# ATSAM4LC2A device description
Architecture: CORTEX-M4; Family: SAM4; Series: SAM4L
Registers are 32-bit, read-write, reset 0x0 unless marked. A register's access mark holds for its fields unless they carry their own. Offsets are from the block's base; [hi:lo] are bit positions; {n}, {i} and the like mark numbered series; 'fields as' and 'values as' point back to an identical list; <NAME> marks a mode.

## USART — Universal Synchronous Asynchronous Receiver Transmitter
Instances: USART{n} {0x40024000+0x4000*n} (n=0..3)
0x00 CR wo reset not defined — Control Register
  [21] LINWKUP <LIN_MODE> — Sends a wakeup signal on the LIN bus
  [20] LINABT <LIN_MODE> — Abort the current LIN transmission
  [19] RTSDIS <LIN_MODE> — Request to Send Disable
    0=No effect; 1=Drives the pin RTS to 1
  [18] RTSEN <LIN_MODE> — Request to Send Enable
    0=No effect; 1=Drives the pin RTS to 0
  [17] DTRDIS <LIN_MODE> — Data Terminal Ready Disable
    0=No effect; 1=Drives the pin DTR to 1
  [16] DTREN <LIN_MODE> — Data Terminal Ready Enable
    0=No effect; 1=Drives the pin DTR at 0
  [15] RETTO <LIN_MODE> — Rearm Time-out
    0=No effect; 1=Restart Time-out
  [14] RSTNACK <LIN_MODE> — Reset Non Acknowledge
    0=No effect; 1=Resets NACK in CSR
  [13] RSTIT <LIN_MODE> — Reset Iterations
    0=No effect; 1=Resets ITERATION in CSR. No effect if the ISO7816 is not enabled
  [12] SENDA <LIN_MODE> — Send Address
    0=No effect; 1=In Multi-drop Mode only, the next character written to the THR is sent with the address bit set
  [11] STTTO <LIN_MODE> — Start Time-out
    0=No effect; 1=Starts waiting for a character before clocking the time-out counter
  [10] STPBRK <LIN_MODE> — Stop Break
    0=No effect; 1=Stops transmission of the break after a minimum of one character length and transmits a high level during 12-bit periods.No effect if no break is being transmitted
  [9] STTBRK <LIN_MODE> — Start Break
    0=No effect; 1=Starts transmission of a break after the characters present in THR and the Transmit Shift Register have been transmitted. No effect if a break is already being transmitted
  [8] RSTSTA <LIN_MODE> — Reset Status Bits
    0=No effect; 1=Resets the status bits PARE, FRAME, OVRE and RXBRK in the CSR
  [7] TXDIS <LIN_MODE> — Transmitter Disable
    0=No effect; 1=Disables the transmitter
  [6] TXEN <LIN_MODE> — Transmitter Enable
    0=No effect; 1=Enables the transmitter if TXDIS is 0
  [5] RXDIS <LIN_MODE> — Receiver Disable
    0=No effect; 1=Disables the receiver
  [4] RXEN <LIN_MODE> — Receiver Enable
    0=No effect; 1=Enables the receiver, if RXDIS is 0
  [3] RSTTX <LIN_MODE> — Reset Transmitter
    0=No effect; 1=Resets the transmitter
  [2] RSTRX <LIN_MODE> — Reset Receiver
    0=No effect; 1=Resets the receiver
  [19] RCS <SPI_MASTER_MODE> — Release SPI Chip Select
    0=No effect; 1=Releases the Slave Select Line NSS (RTS pin)
  [18] FCS <SPI_MASTER_MODE> — Force SPI Chip Select
    0=No effect; 1=Forces the Slave Select Line NSS (RTS pin) to 0, even if USART is no transmitting, in order to address SPI slave devices supporting the CSAAT Mode (Chip Select Active After Transfer)
  [17] DTRDIS <SPI_MASTER_MODE> — Data Terminal Ready Disable
    0=No effect; 1=Drives the pin DTR to 1
  [16] DTREN <SPI_MASTER_MODE> — Data Terminal Ready Enable
    0=No effect; 1=Drives the pin DTR at 0
  [15] RETTO <SPI_MASTER_MODE> — Rearm Time-out
    0=No effect; 1=Restart Time-out
  [14] RSTNACK <SPI_MASTER_MODE> — Reset Non Acknowledge
    0=No effect; 1=Resets NACK in CSR
  [13] RSTIT <SPI_MASTER_MODE> — Reset Iterations
    values as RSTIT<LIN_MODE>
  [12] SENDA <SPI_MASTER_MODE> — Send Address
    values as SENDA<LIN_MODE>
  [11] STTTO <SPI_MASTER_MODE> — Start Time-out
    values as STTTO<LIN_MODE>
  [10] STPBRK <SPI_MASTER_MODE> — Stop Break
    values as STPBRK<LIN_MODE>
  [9] STTBRK <SPI_MASTER_MODE> — Start Break
    values as STTBRK<LIN_MODE>
  [8] RSTSTA <SPI_MASTER_MODE> — Reset Status Bits
    values as RSTSTA<LIN_MODE>
  [7] TXDIS <SPI_MASTER_MODE> — Transmitter Disable
    0=No effect; 1=Disables the transmitter
  [6] TXEN <SPI_MASTER_MODE> — Transmitter Enable
    0=No effect; 1=Enables the transmitter if TXDIS is 0
  [5] RXDIS <SPI_MASTER_MODE> — Receiver Disable
    0=No effect; 1=Disables the receiver
  [4] RXEN <SPI_MASTER_MODE> — Receiver Enable
    0=No effect; 1=Enables the receiver, if RXDIS is 0
  [3] RSTTX <SPI_MASTER_MODE> — Reset Transmitter
    0=No effect; 1=Resets the transmitter
  [2] RSTRX <SPI_MASTER_MODE> — Reset Receiver
    0=No effect; 1=Resets the receiver
  [19] RTSDIS <USART_MODE> — Request to Send Disable
    0=No effect; 1=Drives the pin RTS to 1
  [18] RTSEN <USART_MODE> — Request to Send Enable
    0=No effect; 1=Drives the pin RTS to 0
  [17] DTRDIS <USART_MODE> — Data Terminal Ready Disable
    0=No effect; 1=Drives the pin DTR to 1
  [16] DTREN <USART_MODE> — Data Terminal Ready Enable
    0=No effect; 1=Drives the pin DTR at 0
  [15] RETTO <USART_MODE> — Rearm Time-out
    0=No effect; 1=Restart Time-out
  [14] RSTNACK <USART_MODE> — Reset Non Acknowledge
    0=No effect; 1=Resets NACK in CSR
  [13] RSTIT <USART_MODE> — Reset Iterations
    values as RSTIT<LIN_MODE>
  [12] SENDA <USART_MODE> — Send Address
    values as SENDA<LIN_MODE>
  [11] STTTO <USART_MODE> — Start Time-out
    values as STTTO<LIN_MODE>
  [10] STPBRK <USART_MODE> — Stop Break
    values as STPBRK<LIN_MODE>
  [9] STTBRK <USART_MODE> — Start Break
    values as STTBRK<LIN_MODE>
  [8] RSTSTA <USART_MODE> — Reset Status Bits
    values as RSTSTA<LIN_MODE>
  [7] TXDIS <USART_MODE> — Transmitter Disable
    0=No effect; 1=Disables the transmitter
  [6] TXEN <USART_MODE> — Transmitter Enable
    0=No effect; 1=Enables the transmitter if TXDIS is 0
  [5] RXDIS <USART_MODE> — Receiver Disable
    0=No effect; 1=Disables the receiver
  [4] RXEN <USART_MODE> — Receiver Enable
    0=No effect; 1=Enables the receiver, if RXDIS is 0
  [3] RSTTX <USART_MODE> — Reset Transmitter
    0=No effect; 1=Resets the transmitter
  [2] RSTRX <USART_MODE> — Reset Receiver
    0=No effect; 1=Resets the receiver
0x04 MR — Mode Register
  [28] FILTER <SPI_MODE> — Infrared Receive Line Filter
    0=The USART does not filter the receive line; 1=The USART filters the receive line using a three-sample filter (1/16-bit clock) (2 over 3 majority)
  [26:24] MAX_ITERATION <SPI_MODE> — Max interation
  [23] INVDATA <SPI_MODE> — Inverted data
  [21] DSNACK <SPI_MODE> — Disable Successive NACK
    0=NACK is sent on the ISO line as soon as a parity error occurs in the received character (unless INACK is set); 1=Successive parity errors are counted up to the value specified in the MAX_ITERATION field. These parity errors generatea NACK on the ISO line. As soon as this value is reached, no additional NACK is sent on the ISO line. The flag ITERATION is asserted
  [20] INACK <SPI_MODE> — Inhibit Non Acknowledge
    0=The NACK is generated; 1=The NACK is not generated
  [19] OVER <SPI_MODE> — Oversampling Mode
    0=X16 (16x Oversampling); 1=X8 (8x Oversampling)
  [18] CLKO <SPI_MODE> — Clock Output Select
    0=The USART does not drive the SCK pin; 1=The USART drives the SCK pin if USCLKS does not select the external clock SCK
  [17] MODE9 <SPI_MODE> — 9-bit Character Length
    0=CHRL defines character length; 1=9-bit character length
  [16] CPOL <SPI_MODE> — SPI Clock Polarity
    0=ZERO (The inactive state value of SPCK is logic level zero); 1=ONE (The inactive state value of SPCK is logic level one)
  [15:14] CHMODE <SPI_MODE> — Channel Mode
    0=NORMAL (Normal Mode); 1=ECHO (Automatic Echo. Receiver input is connected to the TXD pin); 2=LOCAL_LOOP (Local Loopback. Transmitter output is connected to the Receiver Input); 3=REMOTE_LOOP (Remote Loopback. RXD pin is internally connected to the TXD pin)
  [13:12] NBSTOP <SPI_MODE> — Number of Stop Bits
    0=1 stop bit; 1=1_5 (1.5 stop bits (Only valid if SYNC=0)); 2=2 stop bits
  [11:9] PAR <SPI_MODE> — Parity Type
    0=EVEN (Even parity); 1=ODD (Odd parity); 2=SPACE (Parity forced to 0 (Space)); 3=MARK (Parity forced to 1 (Mark)); 4=NONE (No Parity); 5=No Parity; 6=MULTI (Multi-drop mode); 7=Multi-drop mode
  [8] CPHA <SPI_MODE> — SPI CLock Phase
    0=Data is changed on the leading edge of SPCK and captured on the following edge of SPCK; 1=Data is captured on the leading edge of SPCK and changed on the following edge of SPCK
  [7:6] CHRL <SPI_MODE> — Character Length.
    {v}={v+5} bits (v=0..3)
  [5:4] USCLKS <SPI_MODE> — Clock Selection
    0=MCK; 1=MCK_DIV; 3=SCK
  [3:0] MODE <SPI_MODE> — Usart Mode
    0=NORMAL; 1=RS485; 2=HARDWARE (Hardware Handshaking); 3=MODEM; 4=ISO7816_T0 (IS07816 Protocol: T = 0); 6=ISO7816_T1 (IS07816 Protocol: T = 1); 8=IRDA; 10=LIN_Master; 11=LIN_Slave; 14=SPI_Master; 15=SPI_Slave
  [31] ONEBIT <USART_MODE> — Start Frame Delimiter selector
    0=Start Frame delimiter is COMMAND or DATA SYNC; 1=Start Frame delimiter is One Bit
  [30] MODSYNC <USART_MODE> — Manchester Synchronization Mode
    0=The Manchester Start bit is a 0 to 1 transition; 1=The Manchester Start bit is a 1 to 0 transition
  [29] MAN <USART_MODE> — Manchester Encoder/Decoder Enable
    0=Manchester Encoder/Decoder is disabled; 1=Manchester Encoder/Decoder is enabled
  [28] FILTER <USART_MODE> — Infrared Receive Line Filter
    values as FILTER<SPI_MODE>
  [26:24] MAX_ITERATION <USART_MODE> — Max interation
  [23] INVDATA <USART_MODE> — Inverted data
  [22] VAR_SYNC <USART_MODE> — Variable synchronization of command/data sync Start Frame Delimiter
    0=User defined configuration of command or data sync field depending on SYNC value; 1=The sync field is updated when a character is written into THR register
  [21] DSNACK <USART_MODE> — Disable Successive NACK
    values as DSNACK<SPI_MODE>
  [20] INACK <USART_MODE> — Inhibit Non Acknowledge
    0=The NACK is generated; 1=The NACK is not generated
  [19] OVER <USART_MODE> — Oversampling Mode
    0=X16 (16x Oversampling); 1=X8 (8x Oversampling)
  [18] CLKO <USART_MODE> — Clock Output Select
    values as CLKO<SPI_MODE>
  [17] MODE9 <USART_MODE> — 9-bit Character Length
    0=CHRL defines character length; 1=9-bit character length
  [16] MSBF <USART_MODE> — Bit Order
    0=LSBF (Least Significant Bit first); 1=MSBF (Most Significant Bit first)
  [15:14] CHMODE <USART_MODE> — Channel Mode
    values as CHMODE<SPI_MODE>
  [13:12] NBSTOP <USART_MODE> — Number of Stop Bits
    values as NBSTOP<SPI_MODE>
  [11:9] PAR <USART_MODE> — Parity Type
    values as PAR<SPI_MODE>
  [8] SYNC <USART_MODE> — Synchronous Mode Select
    0=USART operates in Synchronous Mode; 1=USART operates in Asynchronous Mode
  [7:6] CHRL <USART_MODE> — Character Length.
    {v}={v+5} bits (v=0..3)
  [5:4] USCLKS <USART_MODE> — Clock Selection
    0=MCK; 1=MCK_DIV; 3=SCK
  [3:0] MODE <USART_MODE> — Usart Mode
    values as MODE<SPI_MODE>
0x08 IER wo (atomic set of IMR) — Interrupt Enable Register
  [31] LINHTE <LIN_MODE> — LIN Header Timeout Error Interrupt Enable
    0=No Effect; 1=Enables the interrupt
  [30] LINSTE <LIN_MODE> — LIN Synch Tolerance Error Interrupt Enable
    0=No Effect; 1=Enables the interrupt
  [29] LINSNRE <LIN_MODE> — LIN Slave Not Responding Error Interrupt Enable
  [28] LINCE <LIN_MODE> — LIN Checksum Error Interrupt Enable
  [27] LINIPE <LIN_MODE> — LIN Identifier Parity Interrupt Enable
  [26] LINISFE <LIN_MODE> — LIN Inconsistent Synch Field Error Interrupt Enable
  [25] LINBE <LIN_MODE> — LIN Bus Error Interrupt Enable
  [19] CTSIC <LIN_MODE> — Clear to Send Input Change Interrupt Enable
    0=No Effect; 1=Enables the interrupt
  [18] DCDIC <LIN_MODE> — Data Carrier Detect Input Change Interrupt Enable
    0=No Effect; 1=Enables the interrupt
  [17] DSRIC <LIN_MODE> — Data Set Ready Input Change Enable
    0=No Effect; 1=Enables the interrupt
  [16] RIIC <LIN_MODE> — Ring Indicator Input Change Enable
    0=No Effect; 1=Enables the interrupt
  [15] LINTC <LIN_MODE> — LIN Transfer Conpleted Interrupt Enable
  [14] LINID <LIN_MODE> — LIN Identifier Sent or LIN Identifier Received Interrupt Enable
  [13] NACK <LIN_MODE> — Non Acknowledge or LIN Break Sent or LIN Break Received Interrupt Enable
    0=No Effect; 1=Enables the interrupt
  [12] RXBUFF <LIN_MODE> — Buffer Full Interrupt Enable
    0=No Effect; 1=Enables the interrupt
  [11] TXBUFE <LIN_MODE> — Buffer Empty Interrupt Enable
    0=No Effect; 1=Enables the interrupt
  [10] ITER <LIN_MODE> — Iteration Interrupt Enable
    0=No Effect; 1=Enables the interrupt
  [9] TXEMPTY <LIN_MODE> — Transmitter Empty Interrupt Enable
    0=No Effect; 1=Enables the interrupt
  [8] TIMEOUT <LIN_MODE> — Time-out Interrupt Enable
    0=No Effect; 1=Enables the interrupt
  [7] PARE <LIN_MODE> — Parity Error Interrupt Enable
    0=No Effect; 1=Enables the interrupt
  [6] FRAME <LIN_MODE> — Framing Error Interrupt Enable
    0=No Effect; 1=Enables the interrupt
  [5] OVRE <LIN_MODE> — Overrun Error Interrupt Enable
    0=No Effect; 1=Enables the interrupt
  [2] RXBRK <LIN_MODE> — Receiver Break Interrupt Enable
    0=No Effect; 1=Enables the interrupt
  [1] TXRDY <LIN_MODE> — Transmitter Ready Interrupt Enable
    0=No Effect; 1=Enables the interrupt
  [0] RXRDY <LIN_MODE> — Receiver Ready Interrupt Enable
    0=No Effect; 1=Enables the interrupt
  [19] CTSIC <SPI_SLAVE_MODE> — Clear to Send Input Change Interrupt Enable
    0=No Effect; 1=Enables the interrupt
  [18] DCDIC <SPI_SLAVE_MODE> — Data Carrier Detect Input Change Interrupt Enable
    0=No Effect; 1=Enables the interrupt
  [17] DSRIC <SPI_SLAVE_MODE> — Data Set Ready Input Change Enable
    0=No Effect; 1=Enables the interrupt
  [16] RIIC <SPI_SLAVE_MODE> — Ring Indicator Input Change Enable
    0=No Effect; 1=Enables the interrupt
  [13] NACK <SPI_SLAVE_MODE> — Non Acknowledge Interrupt Enable
    0=No Effect; 1=Enables the interrupt
  [12] RXBUFF <SPI_SLAVE_MODE> — Buffer Full Interrupt Enable
    0=No Effect; 1=Enables the interrupt
  [11] TXBUFE <SPI_SLAVE_MODE> — Buffer Empty Interrupt Enable
    0=No Effect; 1=Enables the interrupt
  [10] UNRE <SPI_SLAVE_MODE> — SPI Underrun Error Interrupt Enable
    0=No Effect; 1=Enables the interrupt
  [9] TXEMPTY <SPI_SLAVE_MODE> — Transmitter Empty Interrupt Enable
    0=No Effect; 1=Enables the interrupt
  [8] TIMEOUT <SPI_SLAVE_MODE> — Time-out Interrupt Enable
    0=No Effect; 1=Enables the interrupt
  [7] PARE <SPI_SLAVE_MODE> — Parity Error Interrupt Enable
    0=No Effect; 1=Enables the interrupt
  [6] FRAME <SPI_SLAVE_MODE> — Framing Error Interrupt Enable
    0=No Effect; 1=Enables the interrupt
  [5] OVRE <SPI_SLAVE_MODE> — Overrun Error Interrupt Enable
    0=No Effect; 1=Enables the interrupt
  [2] RXBRK <SPI_SLAVE_MODE> — Receiver Break Interrupt Enable
    0=No Effect; 1=Enables the interrupt
  [1] TXRDY <SPI_SLAVE_MODE> — Transmitter Ready Interrupt Enable
    0=No Effect; 1=Enables the interrupt
  [0] RXRDY <SPI_SLAVE_MODE> — Receiver Ready Interrupt Enable
    0=No Effect; 1=Enables the interrupt
  [24] MANEA <USART_MODE> — Manchester Error Interrupt Enable
    0=No effect; 1=Enables the interrupt
  [20] MANE <USART_MODE> — Manchester Error Interrupt Enable
  [19] CTSIC <USART_MODE> — Clear to Send Input Change Interrupt Enable
    0=No Effect; 1=Enables the interrupt
  [18] DCDIC <USART_MODE> — Data Carrier Detect Input Change Interrupt Enable
    0=No Effect; 1=Enables the interrupt
  [17] DSRIC <USART_MODE> — Data Set Ready Input Change Enable
    0=No Effect; 1=Enables the interrupt
  [16] RIIC <USART_MODE> — Ring Indicator Input Change Enable
    0=No Effect; 1=Enables the interrupt
  [13] NACK <USART_MODE> — Non Acknowledge Interrupt Enable
    0=No Effect; 1=Enables the interrupt
  [12] RXBUFF <USART_MODE> — Buffer Full Interrupt Enable
    0=No Effect; 1=Enables the interrupt
  [11] TXBUFE <USART_MODE> — Buffer Empty Interrupt Enable
    0=No Effect; 1=Enables the interrupt
  [10] ITER <USART_MODE> — Iteration Interrupt Enable
    0=No Effect; 1=Enables the interrupt
  [9] TXEMPTY <USART_MODE> — Transmitter Empty Interrupt Enable
    0=No Effect; 1=Enables the interrupt
  [8] TIMEOUT <USART_MODE> — Time-out Interrupt Enable
    0=No Effect; 1=Enables the interrupt
  [7] PARE <USART_MODE> — Parity Error Interrupt Enable
    0=No Effect; 1=Enables the interrupt
  [6] FRAME <USART_MODE> — Framing Error Interrupt Enable
    0=No Effect; 1=Enables the interrupt
  [5] OVRE <USART_MODE> — Overrun Error Interrupt Enable
    0=No Effect; 1=Enables the interrupt
  [2] RXBRK <USART_MODE> — Receiver Break Interrupt Enable
    0=No Effect; 1=Enables the interrupt
  [1] TXRDY <USART_MODE> — Transmitter Ready Interrupt Enable
    0=No Effect; 1=Enables the interrupt
  [0] RXRDY <USART_MODE> — Receiver Ready Interrupt Enable
    0=No Effect; 1=Enables the interrupt
0x0C IDR wo (atomic clear of IMR) — Interrupt Disable Register
  [31] LINHTE <LIN_MODE> — LIN Header Timeout Error Interrupt Disable
    0=No Effect; 1=Disables the interrupt
  [30] LINSTE <LIN_MODE> — LIN Synch Tolerance Error Interrupt Disable
    0=No Effect; 1=Disables the interrupt
  [29] LINSNRE <LIN_MODE> — LIN Slave Not Responding Error Interrupt Disable
  [28] LINCE <LIN_MODE> — LIN Checksum Error Interrupt Disable
  [27] LINIPE <LIN_MODE> — LIN Identifier Parity Interrupt Disable
  [26] LINISFE <LIN_MODE> — LIN Inconsistent Synch Field Error Interrupt Disable
  [25] LINBE <LIN_MODE> — LIN Bus Error Interrupt Disable
  [19] CTSIC <LIN_MODE> — Clear to Send Input Change Interrupt Disable
    0=No Effect; 1=Disables the interrupt
  [18] DCDIC <LIN_MODE> — Data Carrier Detect Input Change Interrupt Disable
    0=No Effect; 1=Disables the interrupt
  [17] DSRIC <LIN_MODE> — Data Set Ready Input Change Disable
    0=No Effect; 1=Disables the interrupt
  [16] RIIC <LIN_MODE> — Ring Indicator Input Change Disable
    0=No Effect; 1=Disables the interrupt
  [15] LINTC <LIN_MODE> — LIN Transfer Conpleted Interrupt Disable
  [14] LINID <LIN_MODE> — LIN Identifier Sent or LIN Identifier Received Interrupt Disable
  [13] NACK <LIN_MODE> — Non Acknowledge or LIN Break Sent or LIN Break Received Interrupt Disable
    0=No Effect; 1=Disables the interrupt
  [12] RXBUFF <LIN_MODE> — Buffer Full Interrupt Disable
    0=No Effect; 1=Disables the interrupt
  [11] TXBUFE <LIN_MODE> — Buffer Empty Interrupt Disable
    0=No Effect; 1=Disables the interrupt
  [10] ITER <LIN_MODE> — Iteration Interrupt Disable
    0=No Effect; 1=Disables the interrupt
  [9] TXEMPTY <LIN_MODE> — Transmitter Empty Interrupt Disable
    0=No Effect; 1=Disables the interrupt
  [8] TIMEOUT <LIN_MODE> — Time-out Interrupt Disable
    0=No Effect; 1=Disables the interrupt
  [7] PARE <LIN_MODE> — Parity Error Interrupt Disable
    0=No Effect; 1=Disables the interrupt
  [6] FRAME <LIN_MODE> — Framing Error Interrupt Disable
    0=No Effect; 1=Disables the interrupt
  [5] OVRE <LIN_MODE> — Overrun Error Interrupt Disable
    0=No Effect; 1=Disables the interrupt
  [2] RXBRK <LIN_MODE> — Receiver Break Interrupt Disable
    0=No Effect; 1=Disables the interrupt
  [1] TXRDY <LIN_MODE> — Transmitter Ready Interrupt Disable
    0=No Effect; 1=Disables the interrupt
  [0] RXRDY <LIN_MODE> — Receiver Ready Interrupt Disable
    0=No Effect; 1=Disables the interrupt
  [19] CTSIC <SPI_SLAVE_MODE> — Clear to Send Input Change Interrupt Disable
    0=No Effect; 1=Disables the interrupt
  [18] DCDIC <SPI_SLAVE_MODE> — Data Carrier Detect Input Change Interrupt Disable
    0=No Effect; 1=Disables the interrupt
  [17] DSRIC <SPI_SLAVE_MODE> — Data Set Ready Input Change Disable
    0=No Effect; 1=Disables the interrupt
  [16] RIIC <SPI_SLAVE_MODE> — Ring Indicator Input Change Disable
    0=No Effect; 1=Disables the interrupt
  [13] NACK <SPI_SLAVE_MODE> — Non Acknowledge Interrupt Disable
    0=No Effect; 1=Disables the interrupt
  [12] RXBUFF <SPI_SLAVE_MODE> — Buffer Full Interrupt Disable
    0=No Effect; 1=Disables the interrupt
  [11] TXBUFE <SPI_SLAVE_MODE> — Buffer Empty Interrupt Disable
    0=No Effect; 1=Disables the interrupt
  [10] UNRE <SPI_SLAVE_MODE> — SPI Underrun Error Interrupt Disable
    0=No Effect; 1=Disables the interrupt
  [9] TXEMPTY <SPI_SLAVE_MODE> — Transmitter Empty Interrupt Disable
    0=No Effect; 1=Disables the interrupt
  [8] TIMEOUT <SPI_SLAVE_MODE> — Time-out Interrupt Disable
    0=No Effect; 1=Disables the interrupt
  [7] PARE <SPI_SLAVE_MODE> — Parity Error Interrupt Disable
    0=No Effect; 1=Disables the interrupt
  [6] FRAME <SPI_SLAVE_MODE> — Framing Error Interrupt Disable
    0=No Effect; 1=Disables the interrupt
  [5] OVRE <SPI_SLAVE_MODE> — Overrun Error Interrupt Disable
    0=No Effect; 1=Disables the interrupt
  [2] RXBRK <SPI_SLAVE_MODE> — Receiver Break Interrupt Disable
    0=No Effect; 1=Disables the interrupt
  [1] TXRDY <SPI_SLAVE_MODE> — Transmitter Ready Interrupt Disable
    0=No Effect; 1=Disables the interrupt
  [0] RXRDY <SPI_SLAVE_MODE> — Receiver Ready Interrupt Disable
    0=No Effect; 1=Disables the interrupt
  [24] MANEA <USART_MODE> — Manchester Error Interrupt Disable
    0=No effect; 1=Disables the corresponding interrupt
  [20] MANE <USART_MODE> — Manchester Error Interrupt Disable
  [19] CTSIC <USART_MODE> — Clear to Send Input Change Interrupt Disable
    0=No Effect; 1=Disables the interrupt
  [18] DCDIC <USART_MODE> — Data Carrier Detect Input Change Interrupt Disable
    0=No Effect; 1=Disables the interrupt
  [17] DSRIC <USART_MODE> — Data Set Ready Input Change Disable
    0=No Effect; 1=Disables the interrupt
  [16] RIIC <USART_MODE> — Ring Indicator Input Change Disable
    0=No Effect; 1=Disables the interrupt
  [13] NACK <USART_MODE> — Non Acknowledge Interrupt Disable
    0=No Effect; 1=Disables the interrupt
  [12] RXBUFF <USART_MODE> — Buffer Full Interrupt Disable
    0=No Effect; 1=Disables the interrupt
  [11] TXBUFE <USART_MODE> — Buffer Empty Interrupt Disable
    0=No Effect; 1=Disables the interrupt
  [10] ITER <USART_MODE> — Iteration Interrupt Disable
    0=No Effect; 1=Disables the interrupt
  [9] TXEMPTY <USART_MODE> — Transmitter Empty Interrupt Disable
    0=No Effect; 1=Disables the interrupt
  [8] TIMEOUT <USART_MODE> — Time-out Interrupt Disable
    0=No Effect; 1=Disables the interrupt
  [7] PARE <USART_MODE> — Parity Error Interrupt Disable
    0=No Effect; 1=Disables the interrupt
  [6] FRAME <USART_MODE> — Framing Error Interrupt Disable
    0=No Effect; 1=Disables the interrupt
  [5] OVRE <USART_MODE> — Overrun Error Interrupt Disable
    0=No Effect; 1=Disables the interrupt
  [2] RXBRK <USART_MODE> — Receiver Break Interrupt Disable
    0=No Effect; 1=Disables the interrupt
  [1] TXRDY <USART_MODE> — Transmitter Ready Interrupt Disable
    0=No Effect; 1=Disables the interrupt
  [0] RXRDY <USART_MODE> — Receiver Ready Interrupt Disable
    0=No Effect; 1=Disables the interrupt
0x10 IMR ro — Interrupt Mask Register
  [31] LINHTE <LIN_MODE> — LIN Header Timeout Error Interrupt Mask
    0=The interrupt is disabled; 1=The interrupt is enabled
  [30] LINSTE <LIN_MODE> — LIN Synch Tolerance Error Interrupt Mask
    0=The interrupt is disabled; 1=The interrupt is enabled
  [29] LINSNRE <LIN_MODE> — LIN Slave Not Responding Error Interrupt Mask
  [28] LINCE <LIN_MODE> — LIN Checksum Error Interrupt Mask
  [27] LINIPE <LIN_MODE> — LIN Identifier Parity Interrupt Mask
  [26] LINISFE <LIN_MODE> — LIN Inconsistent Synch Field Error Interrupt Mask
  [25] LINBE <LIN_MODE> — LIN Bus Error Interrupt Mask
  [19] CTSIC <LIN_MODE> — Clear to Send Input Change Interrupt Mask
    0=The interrupt is disabled; 1=The interrupt is enabled
  [18] DCDIC <LIN_MODE> — Data Carrier Detect Input Change Interrupt Mask
    0=The interrupt is disabled; 1=The interrupt is enabled
  [17] DSRIC <LIN_MODE> — Data Set Ready Input Change Mask
    0=The interrupt is disabled; 1=The interrupt is enabled
  [16] RIIC <LIN_MODE> — Ring Indicator Input Change Mask
    0=The interrupt is disabled; 1=The interrupt is enabled
  [15] LINTC <LIN_MODE> — LIN Transfer Conpleted Interrupt Mask
  [14] LINID <LIN_MODE> — LIN Identifier Sent or LIN Received Interrupt Mask
  [13] NACK <LIN_MODE> — Non Acknowledge or LIN Break Sent or LIN Break Received Interrupt Mask
    0=The interrupt is disabled; 1=The interrupt is enabled
  [12] RXBUFF <LIN_MODE> — Buffer Full Interrupt Mask
    0=The interrupt is disabled; 1=The interrupt is enabled
  [11] TXBUFE <LIN_MODE> — Buffer Empty Interrupt Mask
    0=The interrupt is disabled; 1=The interrupt is enabled
  [10] ITER <LIN_MODE> — Iteration Interrupt Mask
    0=The interrupt is disabled; 1=The interrupt is enabled
  [9] TXEMPTY <LIN_MODE> — TXEMPTY Interrupt Mask
    0=The interrupt is disabled; 1=The interrupt is enabled
  [8] TIMEOUT <LIN_MODE> — Time-out Interrupt Mask
    0=The interrupt is disabled; 1=The interrupt is enabled
  [7] PARE <LIN_MODE> — Parity Error Interrupt Mask
    0=The interrupt is disabled; 1=The interrupt is enabled
  [6] FRAME <LIN_MODE> — Framing Error Interrupt Mask
    0=The interrupt is disabled; 1=The interrupt is enabled
  [5] OVRE <LIN_MODE> — Overrun Error Interrupt Mask
    0=The interrupt is disabled; 1=The interrupt is enabled
  [2] RXBRK <LIN_MODE> — Receiver Break Interrupt Mask
    0=The interrupt is disabled; 1=The interrupt is enabled
  [1] TXRDY <LIN_MODE> — TXRDY Interrupt Mask
    0=The interrupt is disabled; 1=The interrupt is enabled
  [0] RXRDY <LIN_MODE> — RXRDY Interrupt Mask
    0=The interrupt is disabled; 1=The interrupt is enabled
  [19] CTSIC <SPI_SLAVE_MODE> — Clear to Send Input Change Interrupt Mask
    0=The interrupt is disabled; 1=The interrupt is enabled
  [18] DCDIC <SPI_SLAVE_MODE> — Data Carrier Detect Input Change Interrupt Mask
    0=The interrupt is disabled; 1=The interrupt is enabled
  [17] DSRIC <SPI_SLAVE_MODE> — Data Set Ready Input Change Mask
    0=The interrupt is disabled; 1=The interrupt is enabled
  [16] RIIC <SPI_SLAVE_MODE> — Ring Indicator Input Change Mask
    0=The interrupt is disabled; 1=The interrupt is enabled
  [13] NACK <SPI_SLAVE_MODE> — Non Acknowledge Interrupt Mask
    0=The interrupt is disabled; 1=The interrupt is enabled
  [12] RXBUFF <SPI_SLAVE_MODE> — Buffer Full Interrupt Mask
    0=The interrupt is disabled; 1=The interrupt is enabled
  [11] TXBUFE <SPI_SLAVE_MODE> — Buffer Empty Interrupt Mask
    0=The interrupt is disabled; 1=The interrupt is enabled
  [10] UNRE <SPI_SLAVE_MODE> — SPI Underrun Error Interrupt Mask
    0=The interrupt is disabled; 1=The interrupt is enabled
  [9] TXEMPTY <SPI_SLAVE_MODE> — TXEMPTY Interrupt Mask
    0=The interrupt is disabled; 1=The interrupt is enabled
  [8] TIMEOUT <SPI_SLAVE_MODE> — Time-out Interrupt Mask
    0=The interrupt is disabled; 1=The interrupt is enabled
  [7] PARE <SPI_SLAVE_MODE> — Parity Error Interrupt Mask
    0=The interrupt is disabled; 1=The interrupt is enabled
  [6] FRAME <SPI_SLAVE_MODE> — Framing Error Interrupt Mask
    0=The interrupt is disabled; 1=The interrupt is enabled
  [5] OVRE <SPI_SLAVE_MODE> — Overrun Error Interrupt Mask
    0=The interrupt is disabled; 1=The interrupt is enabled
  [2] RXBRK <SPI_SLAVE_MODE> — Receiver Break Interrupt Mask
    0=The interrupt is disabled; 1=The interrupt is enabled
  [1] TXRDY <SPI_SLAVE_MODE> — TXRDY Interrupt Mask
    0=The interrupt is disabled; 1=The interrupt is enabled
  [0] RXRDY <SPI_SLAVE_MODE> — RXRDY Interrupt Mask
    0=The interrupt is disabled; 1=The interrupt is enabled
  [24] MANEA <USART_MODE> — Manchester Error Interrupt Mask
    0=The interrupt is disabled; 1=The interrupt is enabled
  [20] MANE <USART_MODE> — Manchester Error Interrupt Mask
  [19] CTSIC <USART_MODE> — Clear to Send Input Change Interrupt Mask
    0=The interrupt is disabled; 1=The interrupt is enabled
  [18] DCDIC <USART_MODE> — Data Carrier Detect Input Change Interrupt Mask
    0=The interrupt is disabled; 1=The interrupt is enabled
  [17] DSRIC <USART_MODE> — Data Set Ready Input Change Mask
    0=The interrupt is disabled; 1=The interrupt is enabled
  [16] RIIC <USART_MODE> — Ring Indicator Input Change Mask
    0=The interrupt is disabled; 1=The interrupt is enabled
  [13] NACK <USART_MODE> — Non Acknowledge Interrupt Mask
    0=The interrupt is disabled; 1=The interrupt is enabled
  [12] RXBUFF <USART_MODE> — Buffer Full Interrupt Mask
    0=The interrupt is disabled; 1=The interrupt is enabled
  [11] TXBUFE <USART_MODE> — Buffer Empty Interrupt Mask
    0=The interrupt is disabled; 1=The interrupt is enabled
  [10] ITER <USART_MODE> — Iteration Interrupt Mask
    0=The interrupt is disabled; 1=The interrupt is enabled
  [9] TXEMPTY <USART_MODE> — TXEMPTY Interrupt Mask
    0=The interrupt is disabled; 1=The interrupt is enabled
  [8] TIMEOUT <USART_MODE> — Time-out Interrupt Mask
    0=The interrupt is disabled; 1=The interrupt is enabled
  [7] PARE <USART_MODE> — Parity Error Interrupt Mask
    0=The interrupt is disabled; 1=The interrupt is enabled
  [6] FRAME <USART_MODE> — Framing Error Interrupt Mask
    0=The interrupt is disabled; 1=The interrupt is enabled
  [5] OVRE <USART_MODE> — Overrun Error Interrupt Mask
    0=The interrupt is disabled; 1=The interrupt is enabled
  [2] RXBRK <USART_MODE> — Receiver Break Interrupt Mask
    0=The interrupt is disabled; 1=The interrupt is enabled
  [1] TXRDY <USART_MODE> — TXRDY Interrupt Mask
    0=The interrupt is disabled; 1=The interrupt is enabled
  [0] RXRDY <USART_MODE> — RXRDY Interrupt Mask
    0=The interrupt is disabled; 1=The interrupt is enabled
0x14 CSR ro — Channel Status Register
  [31] LINHTE <LIN_MODE> — LIN Header Timeout Error
    0=COMM_RX is at 0; 1=COMM_RX is at 1
  [30] LINSTE <LIN_MODE> — LIN Synch Tolerance Error
    0=COMM_TX is at 0; 1=COMM_TX is at 1
  [29] LINSNRE <LIN_MODE> — LIN Slave Not Responding Error
  [28] LINCE <LIN_MODE> — LIN Checksum Error
  [27] LINIPE <LIN_MODE> — LIN Identifier Parity Error
  [26] LINISFE <LIN_MODE> — LIN Inconsistent Synch Field Error
  [25] LINBE <LIN_MODE> — LIN Bit Error
  [23] LINBLS <LIN_MODE> — LIN Bus Line Status
    0=CTS is at 0; 1=CTS is at 1
  [22] DCD <LIN_MODE> — Image of DCD Input
    0=DCD is at 0; 1=DCD is at 1
  [21] DSR <LIN_MODE> — Image of DSR Input
    0=DSR is at 0; 1=DSR is at 1
  [20] RI <LIN_MODE> — Image of RI Input
    0=RI is at 0; 1=RI is at 1
  [19] CTSIC <LIN_MODE> — Clear to Send Input Change Flag
    0=No input change has been detected on the CTS pin since the last read of CSR; 1=At least one input change has been detected on the CTS pin since the last read of CSR
  [18] DCDIC <LIN_MODE> — Data Carrier Detect Input Change Flag
    0=No input change has been detected on the DCD pin since the last read of CSR; 1=At least one input change has been detected on the DCD pin since the last read of CSR
  [17] DSRIC <LIN_MODE> — Data Set Ready Input Change Flag
    0=No input change has been detected on the DSR pin since the last read of CSR; 1=At least one input change has been detected on the DSR pin since the last read of CSR
  [16] RIIC <LIN_MODE> — Ring Indicator Input Change Flag
    0=No input change has been detected on the RI pin since the last read of CSR; 1=At least one input change has been detected on the RI pin since the last read of CSR
  [15] LINTC <LIN_MODE> — LIN Transfer Conpleted
  [14] LINID <LIN_MODE> — LIN Identifier Sent or LIN Identifier Received
  [13] NACK <LIN_MODE> — Non Acknowledge or LIN Break Sent or LIN Break Received
    0=No Non Acknowledge has not been detected since the last RSTNACK; 1=At least one Non Acknowledge has been detected since the last RSTNACK
  [12] RXBUFF <LIN_MODE> — Reception Buffer Full
    0=The signal Buffer Full from the Receive PDC channel is inactive; 1=The signal Buffer Full from the Receive PDC channel is active
  [11] TXBUFE <LIN_MODE> — Transmission Buffer Empty
    0=The signal Buffer Empty from the Transmit PDC channel is inactive; 1=The signal Buffer Empty from the Transmit PDC channel is active
  [10] ITER <LIN_MODE> — Max number of Repetitions Reached
    0=Maximum number of repetitions has not been reached since the last RSIT; 1=Maximum number of repetitions has been reached since the last RSIT
  [9] TXEMPTY <LIN_MODE> — Transmitter Empty
    0=There are characters in either THR or the Transmit Shift Register, or the transmitter is disabled; 1=There is at least one character in either THR or the Transmit Shift Register
  [8] TIMEOUT <LIN_MODE> — Receiver Time-out
    0=There has not been a time-out since the last Start Time-out command or the Time-out Register is 0; 1=There has been a time-out since the last Start Time-out command
  [7] PARE <LIN_MODE> — Parity Error
    0=No parity error has been detected since the last RSTSTA; 1=At least one parity error has been detected since the last RSTSTA
  [6] FRAME <LIN_MODE> — Framing Error
    0=No stop bit has been detected low since the last RSTSTA; 1=At least one stop bit has been detected low since the last RSTSTA
  [5] OVRE <LIN_MODE> — Overrun Error
    0=No overrun error has occurred since since the last RSTSTA; 1=At least one overrun error has occurred since the last RSTSTA
  [2] RXBRK <LIN_MODE> — Break Received/End of Break
    0=No Break received or End of Break detected since the last RSTSTA; 1=Break Received or End of Break detected since the last RSTSTA
  [1] TXRDY <LIN_MODE> — Transmitter Ready
    0=A character is in the THR waiting to be transferred to the Transmit Shift Register, or an STTBRK command has been requested, or the transmitter is disabled. As soon as the transmitter is enabled, TXRDY becomes 1; 1=There is no character in the THR
  [0] RXRDY <LIN_MODE> — Receiver Ready
    0=No complete character has been received since the last read of RHR or the receiver is disabled. If characters werebeing received when the receiver was disabled, RXRDY changes to 1 when the receiver is enabled; 1=At least one complete character has been received and RHR has not yet been read
  [23] CTS <SPI_SLAVE_MODE> — Image of CTS Input
    0=CTS is at 0; 1=CTS is at 1
  [22] DCD <SPI_SLAVE_MODE> — Image of DCD Input
    0=DCD is at 0; 1=DCD is at 1
  [21] DSR <SPI_SLAVE_MODE> — Image of DSR Input
    0=DSR is at 0; 1=DSR is at 1
  [20] RI <SPI_SLAVE_MODE> — Image of RI Input
    0=RI is at 0; 1=RI is at 1
  [19] CTSIC <SPI_SLAVE_MODE> — Clear to Send Input Change Flag
    values as CTSIC<LIN_MODE>
  [18] DCDIC <SPI_SLAVE_MODE> — Data Carrier Detect Input Change Flag
    values as DCDIC<LIN_MODE>
  [17] DSRIC <SPI_SLAVE_MODE> — Data Set Ready Input Change Flag
    values as DSRIC<LIN_MODE>
  [16] RIIC <SPI_SLAVE_MODE> — Ring Indicator Input Change Flag
    values as RIIC<LIN_MODE>
  [13] NACK <SPI_SLAVE_MODE> — Non Acknowledge
    values as NACK<LIN_MODE>
  [12] RXBUFF <SPI_SLAVE_MODE> — Reception Buffer Full
    values as RXBUFF<LIN_MODE>
  [11] TXBUFE <SPI_SLAVE_MODE> — Transmission Buffer Empty
    values as TXBUFE<LIN_MODE>
  [10] UNRE <SPI_SLAVE_MODE> — SPI Underrun Error
    0=No SPI underrun error has occurred since the last RSTSTA; 1=At least one SPI underrun error has occurred since the last RSTSTA
  [9] TXEMPTY <SPI_SLAVE_MODE> — Transmitter Empty
    values as TXEMPTY<LIN_MODE>
  [8] TIMEOUT <SPI_SLAVE_MODE> — Receiver Time-out
    values as TIMEOUT<LIN_MODE>
  [7] PARE <SPI_SLAVE_MODE> — Parity Error
    values as PARE<LIN_MODE>
  [6] FRAME <SPI_SLAVE_MODE> — Framing Error
    values as FRAME<LIN_MODE>
  [5] OVRE <SPI_SLAVE_MODE> — Overrun Error
    values as OVRE<LIN_MODE>
  [2] RXBRK <SPI_SLAVE_MODE> — Break Received/End of Break
    values as RXBRK<LIN_MODE>
  [1] TXRDY <SPI_SLAVE_MODE> — Transmitter Ready
    values as TXRDY<LIN_MODE>
  [0] RXRDY <SPI_SLAVE_MODE> — Receiver Ready
    values as RXRDY<LIN_MODE>
  [24] MANERR <USART_MODE> — Manchester Error
    0=No Manchester error has been detected since the last RSTSTA; 1=At least one Manchester error has been detected since the last RSTSTA
  [23] CTS <USART_MODE> — Image of CTS Input
    0=CTS is at 0; 1=CTS is at 1
  [22] DCD <USART_MODE> — Image of DCD Input
    0=DCD is at 0; 1=DCD is at 1
  [21] DSR <USART_MODE> — Image of DSR Input
    0=DSR is at 0; 1=DSR is at 1
  [20] RI <USART_MODE> — Image of RI Input
    0=RI is at 0; 1=RI is at 1
  [19] CTSIC <USART_MODE> — Clear to Send Input Change Flag
    values as CTSIC<LIN_MODE>
  [18] DCDIC <USART_MODE> — Data Carrier Detect Input Change Flag
    values as DCDIC<LIN_MODE>
  [17] DSRIC <USART_MODE> — Data Set Ready Input Change Flag
    values as DSRIC<LIN_MODE>
  [16] RIIC <USART_MODE> — Ring Indicator Input Change Flag
    values as RIIC<LIN_MODE>
  [13] NACK <USART_MODE> — Non Acknowledge
    values as NACK<LIN_MODE>
  [12] RXBUFF <USART_MODE> — Reception Buffer Full
    values as RXBUFF<LIN_MODE>
  [11] TXBUFE <USART_MODE> — Transmission Buffer Empty
    values as TXBUFE<LIN_MODE>
  [10] ITER <USART_MODE> — Max number of Repetitions Reached
    values as ITER<LIN_MODE>
  [9] TXEMPTY <USART_MODE> — Transmitter Empty
    values as TXEMPTY<LIN_MODE>
  [8] TIMEOUT <USART_MODE> — Receiver Time-out
    values as TIMEOUT<LIN_MODE>
  [7] PARE <USART_MODE> — Parity Error
    values as PARE<LIN_MODE>
  [6] FRAME <USART_MODE> — Framing Error
    values as FRAME<LIN_MODE>
  [5] OVRE <USART_MODE> — Overrun Error
    values as OVRE<LIN_MODE>
  [2] RXBRK <USART_MODE> — Break Received/End of Break
    values as RXBRK<LIN_MODE>
  [1] TXRDY <USART_MODE> — Transmitter Ready
    values as TXRDY<LIN_MODE>
  [0] RXRDY <USART_MODE> — Receiver Ready
    values as RXRDY<LIN_MODE>
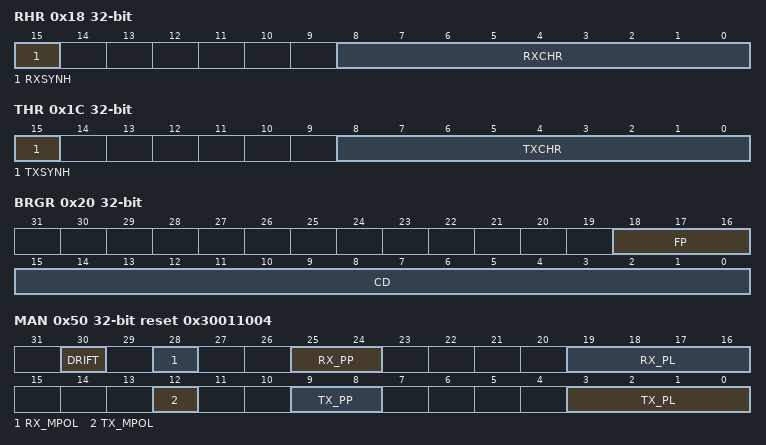
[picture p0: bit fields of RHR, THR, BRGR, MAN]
0x18 RHR ro — Receiver Holding Register
  [15] RXSYNH — Received Sync
    0=Last character received is a Data; 1=Last character received is a Command
  [8:0] RXCHR — Received Character
0x1C THR wo — Transmitter Holding Register
  [15] TXSYNH — Sync Field to be transmitted
    0=The next character sent is encoded as a data. Start Frame Delimiter is DATA SYNC; 1=The next character sent is encoded as a command. Start Frame Delimiter is COMMAND SYNC
  [8:0] TXCHR — Character to be Transmitted
0x20 BRGR — Baud Rate Generator Register
  [18:16] FP — Fractional Part
    0=Fractional divider is disabled
  [15:0] CD — Clock Divisor
    0=DISABLE (Disables the clock); 1=BYPASS (Clock Divisor Bypass); 2=Baud Rate (Asynchronous Mode) = Selected Clock/(16 x CD) or (8 x CD); Baud Rate (Synchronous Mode) = Selected Clock/CD;
0x24 RTOR — Receiver Time-out Register
  [16:0] TO — Time-out Value
    0=DISABLE (Disables the RX Time-out function)
0x28 TTGR — Transmitter Timeguard Register
  [7:0] TG — Timeguard Value
    0=DISABLE (Disables the TX Timeguard function.)
0x40 FIDI reset 0x174 — FI DI Ratio Register
  [10:0] FI_DI_RATIO — FI Over DI Ratio Value
    0=DISABLE (Baud Rate = 0)
0x44 NER ro — Number of Errors Register
  [7:0] NB_ERRORS — Error number during ISO7816 transfers
0x4C IFR — IrDA Filter Register
  [7:0] IRDA_FILTER
0x50 MAN reset 0x30011004 — Manchester Configuration Register
  [30] DRIFT — Drift compensation
    0=The USART can not recover from an important clock drift; 1=The USART can recover from clock drift. The 16X clock mode must be enabled
  [28] RX_MPOL — Receiver Manchester Polarity
    0=Logic Zero is coded as a zero-to-one transition, Logic One is coded as a one-to-zero transition; 1=Logic Zero is coded as a one-to-zero transition, Logic One is coded as a zero-to-one transition
  [25:24] RX_PP — Receiver Preamble Pattern detected
    0=ALL_ONE; 1=ALL_ZERO; 2=ZERO_ONE; 3=ONE_ZERO
  [19:16] RX_PL — Receiver Preamble Length
    0=The receiver preamble pattern detection is disabled
  [12] TX_MPOL — Transmitter Manchester Polarity
    values as RX_MPOL
  [9:8] TX_PP — Transmitter Preamble Pattern
    0=ALL_ONE; 1=ALL_ZERO; 2=ZERO_ONE; 3=ONE_ZERO
  [3:0] TX_PL — Transmitter Preamble Length
    0=The Transmitter Preamble pattern generation is disabled
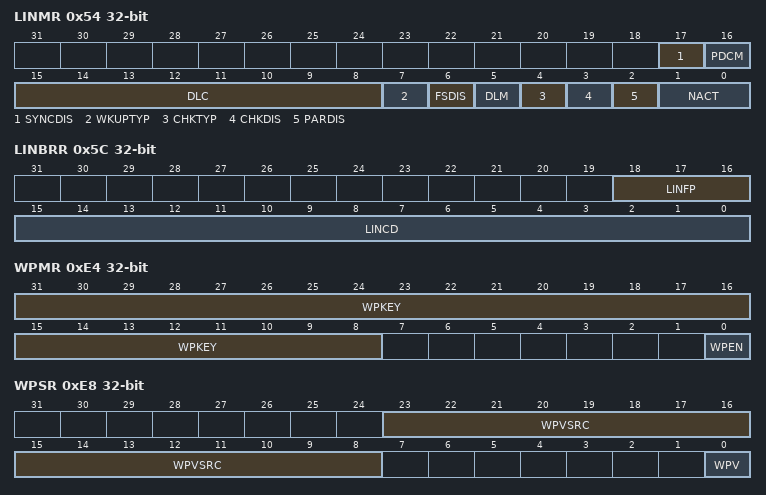
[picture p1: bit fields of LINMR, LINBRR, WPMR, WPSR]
0x54 LINMR — LIN Mode Register
  [17] SYNCDIS — Synchronization Disable
  [16] PDCM — PDC Mode
  [15:8] DLC — Data Length Control
  [7] WKUPTYP — Wakeup Signal Type
  [6] FSDIS — Frame Slot Mode Disable
  [5] DLM — Data Length Mode
  [4] CHKTYP — Checksum Type
  [3] CHKDIS — Checksum Disable
  [2] PARDIS — Parity Disable
  [1:0] NACT — LIN Node Action
    0=PUBLISH (The LIN Controller transmits the response); 1=SUBSCRIBE (The LIN Controller receives the response); 2=IGNORE (The LIN Controller doesn't transmit and doesn't receive the response)
0x58 LINIR — LIN Identifier Register
  [7:0] IDCHR — Identifier Character
0x5C LINBRR ro — LIN Baud Rate Register
  [18:16] LINFP — Fractional Part after Synchronization
  [15:0] LINCD — Clock Divider after Synchronization
0xE4 WPMR — Write Protect Mode Register
  [31:8] WPKEY — Write Protect Key
  [0] WPEN — Write Protect Enable
    0=Disables the Write Protect if WPKEY corresponds to 0x858365 ('USA' in ACII); 1=Enables the Write Protect if WPKEY corresponds to 0x858365 ('USA' in ACII)
0xE8 WPSR ro — Write Protect Status Register
  [23:8] WPVSRC — Write Protect Violation Source
  [0] WPV — Write Protect Violation Status
    0=No Write Protect Violation has occurred since the last read of the WPSR register; 1=A Write Protect Violation has occurred since the last read of the WPSR register. If this violation is an unauthorized attempt to write a protected register, the associated violation is reported into field WPVSRC
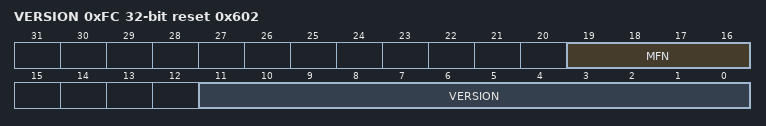
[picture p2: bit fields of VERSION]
0xFC VERSION ro reset 0x602
  [19:16] MFN, [11:0] VERSION
